AUTOSAR XML (schema 4-0-3)
standard types defined: UInt32, UInt8
package /AUTOSAR_Platform/DataConstrs
  range DC_UInt8: raw 0..255
package /PATAC/MSM/ComponentTypes
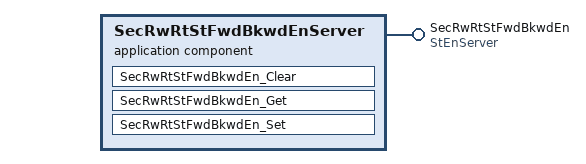
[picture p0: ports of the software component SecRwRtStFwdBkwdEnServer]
  application sw component type SecRwRtStFwdBkwdEnServer
    provide port SecRwRtStFwdBkwdEn: provided-com-specs=[{operation=Clear, queue-length=1}, {operation=Get, queue-length=1}, {operation=Set, queue-length=1}], provided-interface=StEnServer
    behavior SecRwRtStFwdBkwdEnServer_InternalBehavior
      operation invoked event OIT_SecRwRtStFwdBkwdEn_Clear_SecRwRtStFwdBkwdEn_Clear: start-on-event=SecRwRtStFwdBkwdEn_Clear, operation=SecRwRtStFwdBkwdEn.Clear
      operation invoked event OIT_SecRwRtStFwdBkwdEn_Get_SecRwRtStFwdBkwdEn_Get: start-on-event=SecRwRtStFwdBkwdEn_Get, operation=SecRwRtStFwdBkwdEn.Get
      operation invoked event OIT_SecRwRtStFwdBkwdEn_Set_SecRwRtStFwdBkwdEn_Set: start-on-event=SecRwRtStFwdBkwdEn_Set, operation=SecRwRtStFwdBkwdEn.Set
      runnable SecRwRtStFwdBkwdEn_Clear
      runnable SecRwRtStFwdBkwdEn_Get
      runnable SecRwRtStFwdBkwdEn_Set
  swc implementation SecRwRtStFwdBkwdEnServer_Implementation: behavior=SecRwRtStFwdBkwdEnServer_InternalBehavior
    code-descriptors:
      code Default: artifact-descriptors=autosar-engineering-object={short-label=Default, category=SWSRC}
package /PATAC/MSM/ModeAdjust/PortInterface
  client server interface StEnServer
    operation Clear
      arg data: type=UInt8, direction=IN, server-argument-impl-policy=USE-ARGUMENT-TYPE
    operation Get
      arg data: type=UInt32, direction=OUT, server-argument-impl-policy=USE-ARGUMENT-TYPE
    operation Set
      arg data: type=UInt8, direction=IN, server-argument-impl-policy=USE-ARGUMENT-TYPE
